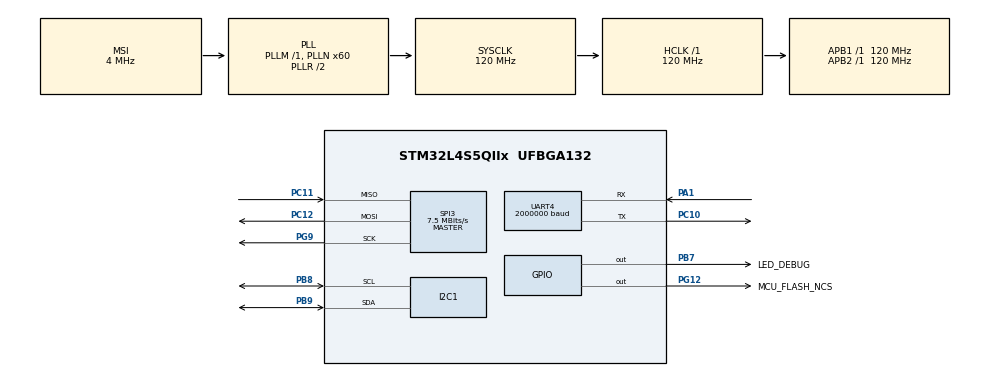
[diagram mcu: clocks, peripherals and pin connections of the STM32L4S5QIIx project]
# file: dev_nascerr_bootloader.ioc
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Dma.Request0=SPI3_RX
Dma.Request1=SPI3_TX
Dma.SPI3_RX.0.Direction=DMA_PERIPH_TO_MEMORY
Dma.SPI3_RX.0.EventEnable=DISABLE
Dma.SPI3_RX.0.Instance=DMA1_Channel1
Dma.SPI3_RX.0.MemDataAlignment=DMA_MDATAALIGN_BYTE
Dma.SPI3_RX.0.MemInc=DMA_MINC_ENABLE
Dma.SPI3_RX.0.Mode=DMA_NORMAL
Dma.SPI3_RX.0.PeriphDataAlignment=DMA_PDATAALIGN_BYTE
Dma.SPI3_RX.0.PeriphInc=DMA_PINC_DISABLE
Dma.SPI3_RX.0.Polarity=HAL_DMAMUX_REQUEST_GEN_RISING
Dma.SPI3_RX.0.Priority=DMA_PRIORITY_LOW
Dma.SPI3_RX.0.RequestNumber=1
Dma.SPI3_RX.0.SignalID=NONE
Dma.SPI3_RX.0.SyncEnable=DISABLE
Dma.SPI3_RX.0.SyncPolarity=HAL_DMAMUX_SYNC_NO_EVENT
Dma.SPI3_RX.0.SyncRequestNumber=1
Dma.SPI3_RX.0.SyncSignalID=NONE
Dma.SPI3_TX.1.Direction=DMA_MEMORY_TO_PERIPH
Dma.SPI3_TX.1.EventEnable=DISABLE
Dma.SPI3_TX.1.Instance=DMA1_Channel2
Dma.SPI3_TX.1.MemDataAlignment=DMA_MDATAALIGN_BYTE
Dma.SPI3_TX.1.MemInc=DMA_MINC_ENABLE
Dma.SPI3_TX.1.Mode=DMA_NORMAL
Dma.SPI3_TX.1.PeriphDataAlignment=DMA_PDATAALIGN_BYTE
Dma.SPI3_TX.1.PeriphInc=DMA_PINC_DISABLE
Dma.SPI3_TX.1.Polarity=HAL_DMAMUX_REQUEST_GEN_RISING
Dma.SPI3_TX.1.Priority=DMA_PRIORITY_LOW
Dma.SPI3_TX.1.RequestNumber=1
Dma.SPI3_TX.1.SignalID=NONE
Dma.SPI3_TX.1.SyncEnable=DISABLE
Dma.SPI3_TX.1.SyncPolarity=HAL_DMAMUX_SYNC_NO_EVENT
Dma.SPI3_TX.1.SyncRequestNumber=1
Dma.SPI3_TX.1.SyncSignalID=NONE
HASH.SecureHashAlgorithmType=SHA256
HASH.pKey=__NULL
I2C1.OwnAddress=0x55
I2C1.Timing=0x30A175AB
IWDG.Prescaler=IWDG_PRESCALER_64
IWDG.Reload=500
Mcu.Family=STM32L4
Mcu.Name=STM32L4S5QIIx
Mcu.Package=UFBGA132
NVIC.DMA1_Channel1_IRQn=true\:5\:0\:true\:false\:true\:false\:true\:true
NVIC.DMA1_Channel2_IRQn=true\:5\:0\:true\:false\:true\:false\:true\:true
NVIC.I2C1_EV_IRQn=true\:5\:0\:true\:false\:true\:true\:true\:true
NVIC.PriorityGroup=NVIC_PRIORITYGROUP_4
NVIC.SPI3_IRQn=true\:5\:0\:true\:false\:true\:true\:true\:true
NVIC.TIM6_DAC_IRQn=true\:15\:0\:false\:false\:true\:false\:true\:true
NVIC.TimeBase=TIM6_DAC_IRQn
NVIC.TimeBaseIP=TIM6
PA1.Mode=Asynchronous
PA1.Signal=UART4_RX
PB7.GPIO_Label=LED_DEBUG
PB7.Signal=GPIO_Output
PB8.Mode=I2C
PB8.Signal=I2C1_SCL
PB9.Mode=I2C
PB9.Signal=I2C1_SDA
PC10.Mode=Asynchronous
PC10.Signal=UART4_TX
PC11.Mode=Full_Duplex_Master
PC11.Signal=SPI3_MISO
PC12.Mode=Full_Duplex_Master
PC12.Signal=SPI3_MOSI
PG12.GPIO_Label=MCU_FLASH_NCS
PG12.GPIO_Speed=GPIO_SPEED_FREQ_HIGH
PG12.PinState=GPIO_PIN_SET
PG12.Signal=GPIO_Output
PG9.Mode=Full_Duplex_Master
PG9.Signal=SPI3_SCK
ProjectManager.HeapSize=0x200
ProjectManager.StackSize=0x400
ProjectManager.TargetToolchain=STM32CubeIDE
RCC.ADCFreq_Value=16000000
RCC.AHBFreq_Value=120000000
RCC.APB1Freq_Value=120000000
RCC.APB1TimFreq_Value=120000000
RCC.APB2Freq_Value=120000000
RCC.APB2TimFreq_Value=120000000
RCC.CortexFreq_Value=120000000
RCC.HCLKFreq_Value=120000000
RCC.HSE_VALUE=8000000
RCC.HSI48_VALUE=48000000
RCC.HSI_VALUE=16000000
RCC.LSE_VALUE=32768
RCC.MSI_VALUE=4000000
RCC.PLLN=60
RCC.SYSCLKFreq_VALUE=120000000
RCC.SYSCLKSource=RCC_SYSCLKSOURCE_PLLCLK
RCC.USBFreq_Value=16000000
RCC.VCOOutputFreq_Value=240000000
SPI3.BaudRatePrescaler=SPI_BAUDRATEPRESCALER_16
SPI3.CalculateBaudRate=7.5 MBits/s
SPI3.DataSize=SPI_DATASIZE_8BIT
SPI3.Direction=SPI_DIRECTION_2LINES
SPI3.Mode=SPI_MODE_MASTER
SPI3.VirtualType=VM_MASTER
UART4.BaudRate=2000000
VP_HASH_VS_HASH.Mode=HASH_Activate
VP_IWDG_VS_IWDG.Mode=IWDG_Activate
VP_SYS_VS_tim6.Mode=TIM6
board=custom

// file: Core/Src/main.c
/* USER CODE BEGIN Header */
/**
  ******************************************************************************
  * @file           : main.c
  * @brief          : Main program body
  ******************************************************************************
  * @attention
  *
  * Copyright (c) 2025 STMicroelectronics.
  * All rights reserved.
  *
  * This software is licensed under terms that can be found in the LICENSE file
  * in the root directory of this software component.
  * If no LICENSE file comes with this software, it is provided AS-IS.
  *
  ******************************************************************************
  */
/* USER CODE END Header */
#include "main.h"
#include "dma.h"
#include "hash.h"
#include "i2c.h"
#include "spi.h"
#include "usart.h"
#include "gpio.h"

/* USER CODE BEGIN Includes */
#include "NASCERR_DB.h"
#include "NASCERR_Bootloader.h"
#include "i2c_slave.h"
/* USER CODE END Includes */

void SystemClock_Config(void);

/* USER CODE BEGIN 0 */

#include "nascerr_db.h"
//#include "nascerr_log.h"  // ou seu sistema de log preferido

#include "stm32l4xx_hal.h"
#include <string.h>
#include <stdio.h>

/* USER CODE END 0 */

int main(void)
{

  /* MCU Configuration--------------------------------------------------------*/

  /* Reset of all peripherals, Initializes the Flash interface and the Systick. */
  HAL_Init();

  /* Configure the system clock */
  SystemClock_Config();

  /* Initialize all configured peripherals */
  MX_GPIO_Init();
  MX_DMA_Init();
  MX_SPI3_Init();
  MX_HASH_Init();
  MX_UART4_Init();
  MX_I2C1_Init();
  /* USER CODE BEGIN 2 */
  DEBUG_PRINT(LOG_INFO, "BOOTLOADER NASCERR INICIADO \r\n");
  i2c_slave_init();
  nascerr_db_init();
  nascerr_bootloader_FSM_Init();
  /* USER CODE END 2 */

  /* Infinite loop */
  /* USER CODE BEGIN WHILE */
  while (1)
  {
	  nascerr_bootloader_FSM_Run();
    /* USER CODE END WHILE */

  }
}

void SystemClock_Config(void)
{
  RCC_OscInitTypeDef RCC_OscInitStruct = {0};
  RCC_ClkInitTypeDef RCC_ClkInitStruct = {0};

  /** Configure the main internal regulator output voltage
  */
  if (HAL_PWREx_ControlVoltageScaling(PWR_REGULATOR_VOLTAGE_SCALE1_BOOST) != HAL_OK)
  {
    Error_Handler();
  }

  /** Initializes the RCC Oscillators according to the specified parameters
  * in the RCC_OscInitTypeDef structure.
  */
  RCC_OscInitStruct.OscillatorType = RCC_OSCILLATORTYPE_LSI|RCC_OSCILLATORTYPE_MSI;
  RCC_OscInitStruct.LSIState = RCC_LSI_ON;
  RCC_OscInitStruct.MSIState = RCC_MSI_ON;
  RCC_OscInitStruct.MSICalibrationValue = 0;
  RCC_OscInitStruct.MSIClockRange = RCC_MSIRANGE_6;
  RCC_OscInitStruct.PLL.PLLState = RCC_PLL_ON;
  RCC_OscInitStruct.PLL.PLLSource = RCC_PLLSOURCE_MSI;
  RCC_OscInitStruct.PLL.PLLM = 1;
  RCC_OscInitStruct.PLL.PLLN = 60;
  RCC_OscInitStruct.PLL.PLLP = RCC_PLLP_DIV2;
  RCC_OscInitStruct.PLL.PLLQ = RCC_PLLQ_DIV2;
  RCC_OscInitStruct.PLL.PLLR = RCC_PLLR_DIV2;
  if (HAL_RCC_OscConfig(&RCC_OscInitStruct) != HAL_OK)
  {
    Error_Handler();
  }

  /** Initializes the CPU, AHB and APB buses clocks
  */
  RCC_ClkInitStruct.ClockType = RCC_CLOCKTYPE_HCLK|RCC_CLOCKTYPE_SYSCLK
                              |RCC_CLOCKTYPE_PCLK1|RCC_CLOCKTYPE_PCLK2;
  RCC_ClkInitStruct.SYSCLKSource = RCC_SYSCLKSOURCE_PLLCLK;
  RCC_ClkInitStruct.AHBCLKDivider = RCC_SYSCLK_DIV1;
  RCC_ClkInitStruct.APB1CLKDivider = RCC_HCLK_DIV1;
  RCC_ClkInitStruct.APB2CLKDivider = RCC_HCLK_DIV1;

  if (HAL_RCC_ClockConfig(&RCC_ClkInitStruct, FLASH_LATENCY_5) != HAL_OK)
  {
    Error_Handler();
  }
}

void HAL_TIM_PeriodElapsedCallback(TIM_HandleTypeDef *htim)
{
  if (htim->Instance == TIM6)
  {
    HAL_IncTick();
  }
  /* USER CODE BEGIN Callback 1 */
  if (htim->Instance == TIM6)
  {
    nascerr_systimer_refresh();
  }
  /* USER CODE END Callback 1 */
}

void Error_Handler(void)
{
  __disable_irq();
  while (1)
  {
  }
}
